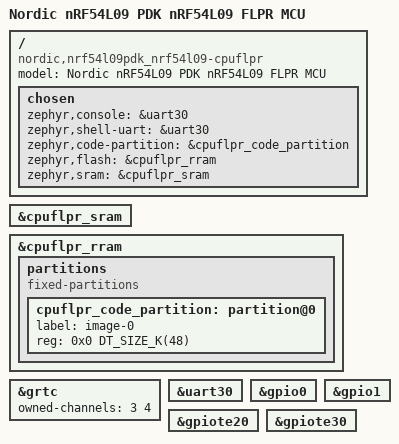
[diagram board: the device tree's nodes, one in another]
/*
 * Copyright (c) 2025 Nordic Semiconductor ASA
 *
 * SPDX-License-Identifier: Apache-2.0
 */

/dts-v1/;
#include <nordic/nrf54l09_enga_cpuflpr.dtsi>
#include "nrf54l09pdk_nrf54l09-common.dtsi"

/ {
	model = "Nordic nRF54L09 PDK nRF54L09 FLPR MCU";
	compatible = "nordic,nrf54l09pdk_nrf54l09-cpuflpr";

	chosen {
		zephyr,console = &uart30;
		zephyr,shell-uart = &uart30;
		zephyr,code-partition = &cpuflpr_code_partition;
		zephyr,flash = &cpuflpr_rram;
		zephyr,sram = &cpuflpr_sram;
	};
};

&cpuflpr_sram {
	status = "okay";
};

&cpuflpr_rram {
	partitions {
		compatible = "fixed-partitions";
		#address-cells = <1>;
		#size-cells = <1>;

		cpuflpr_code_partition: partition@0 {
			label = "image-0";
			reg = <0x0 DT_SIZE_K(48)>;
		};
	};
};

&grtc {
	owned-channels = <3 4>;
	status = "okay";
};

&uart30 {
	status = "okay";
};

&gpio0 {
	status = "okay";
};

&gpio1 {
	status = "okay";
};

&gpiote20 {
	status = "okay";
};

&gpiote30 {
	status = "okay";
};
